# CH32H417 register map
Vendor: WCH Ltd.; File version: 1.2
Registers are 32-bit, read-write, reset 0x0 unless marked. A register's access mark holds for its fields unless they carry their own. Offsets are from the block's base; [hi:lo] are bit positions.

## ECDC
Base 0x40016C00
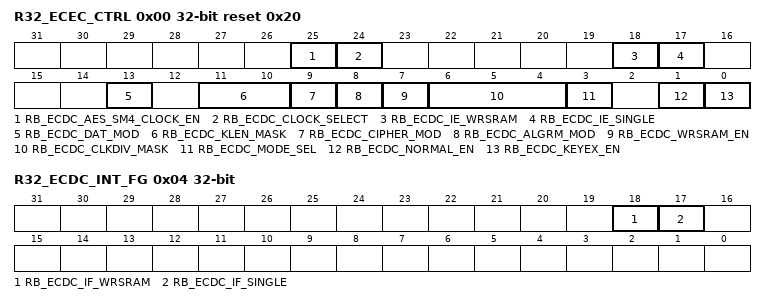
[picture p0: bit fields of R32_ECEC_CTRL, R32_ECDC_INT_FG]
0x00 R32_ECEC_CTRL access per field reset 0x20 — ECED AES/SM4 register
  [25] RB_ECDC_AES_SM4_CLOCK_EN rw — ECED AES/SM4 clock enabled
  [24] RB_ECDC_CLOCK_SELECT rw — ECED AES/SM4 clock selection
  [18] RB_ECDC_IE_WRSRAM wo — Memory to memory encryption and decryption completion interrupt enable
  [17] RB_ECDC_IE_SINGLE rw — Single encryption and decryption completion interrupt enable
  [13] RB_ECDC_DAT_MOD wo — source data and result data is bit endian
  [11:10] RB_ECDC_KLEN_MASK rw — Key length setting
  [9] RB_ECDC_CIPHER_MOD rw — Block cipher mode selection
  [8] RB_ECDC_ALGRM_MOD rw — Encryption and decryption algorithm mode selection
  [7] RB_ECDC_WRSRAM_EN rw — module dma enable
  [6:4] RB_ECDC_CLKDIV_MASK rw — Clock divide factor
  [3] RB_ECDC_MODE_SEL rw — ECDC mode select
  [1] RB_ECDC_NORMAL_EN rw — Enable the encryption and decryption to work in the normal encryption and decryption mode
  [0] RB_ECDC_KEYEX_EN rw — enable key expansion
0x04 R32_ECDC_INT_FG — Interupt flag register
  [18] RB_ECDC_IF_WRSRAM — Memory to memory encryption and decryption completion interrupt flag
  [17] RB_ECDC_IF_SINGLE — Single encryption and decryption completion interrupt flag
0x08 R32_ECDC_KEY_255T224 — User key 224-255 register
  [31:0] RB_ECDC_KEY_255T224
0x0C R32_ECDC_KEY_223T192 — User key 192-223 register
  [31:0] RB_ECDC_KEY_223T192
0x10 R32_ECDC_KEY_191T160 — User key 160-191 register
  [31:0] RB_ECDC_KEY_191T160
0x14 R32_ECDC_KEY_159T128 — User key 128-159 register
  [31:0] RB_ECDC_KEY_159T128
0x18 R32_ECDC_KEY_127T96 — User key 96-127 register
  [31:0] RB_ECDC_KEY_127T96
0x1C R32_ECDC_KEY_95T64 — User key 64-95 register
  [31:0] RB_ECDC_KEY_95T64
0x20 R32_ECDC_KEY_63T32 — User key 32-63 register
  [31:0] RB_ECDC_KEY_63T32
0x24 R32_ECDC_KEY_31T0 — User key 0-31 register
  [31:0] RB_ECDC_KEY_31T0
0x28 R32_ECDC_IV_127T96 — CTR mode count 96-127 register
  [31:0] RB_ECDC_IV_127T96
0x2C R32_ECDC_IV_95T64 — CTR mode count 64-95 register
  [31:0] RB_ECDC_IV_95T64
0x30 R32_ECDC_IV_63T32 — CTR mode count 32-63 register
  [31:0] RB_ECDC_IV_63T32
0x34 R32_ECDC_IV_31T0 — CTR mode count 0-31 register
  [31:0] RB_ECDC_IV_31T0
0x40 R32_ECDC_SGSD_127T96 — Single encryption and decryption of original data 96-127 register
  [31:0] RB_ECDC_SGSD_127T96
0x44 R32_ECDC_SGSD_95T64 — Single encryption and decryption of original data 64-95 register
  [31:0] RB_ECDC_SGSD_95T64
0x48 R32_ECDC_SGSD_63T32 — Single encryption and decryption of original data 32-63 register
  [31:0] RB_ECDC_SGSD_63T32
0x4C R32_ECDC_SGSD_31T0 — Single encryption and decryption of original data 0-31 register
  [31:0] RB_ECDC_SGSD_31T0
0x50 R32_ECDC_SGRT_127T96 — Single encryption and decryption result 96-127 register
  [31:0] RB_ECDC_SGRT_127T96
0x54 R32_ECDC_SGRT_95T64 — Single encryption and decryption result 64-95 register
  [31:0] RB_ECDC_SGRT_95T64
0x58 R32_ECDC_SGRT_63T32 — Single encryption and decryption result 0-31 register
  [31:0] RB_ECDC_SGRT_63T32
0x5C RB_ECDC_SGRT_31T0 — Single encryption and decryption result 0-31 register
0x60 R32_ECDC_SRC_ADDR — encryption and decryption sram start address register
  [31:0] RB_ECDC_SRC_ADDR
0x64 R32_ECDC_DST_ADDR — encryption and decryption sram destination address register
  [31:0] RB_ECDC_DST_ADDR
0x68 R32_ECDC_SRAM_LEN — encryption and decryption sram size register
  [12:0] RB_ECDC_SRAM_LEN

## HSADC — High speed ADC
Base 0x40017400
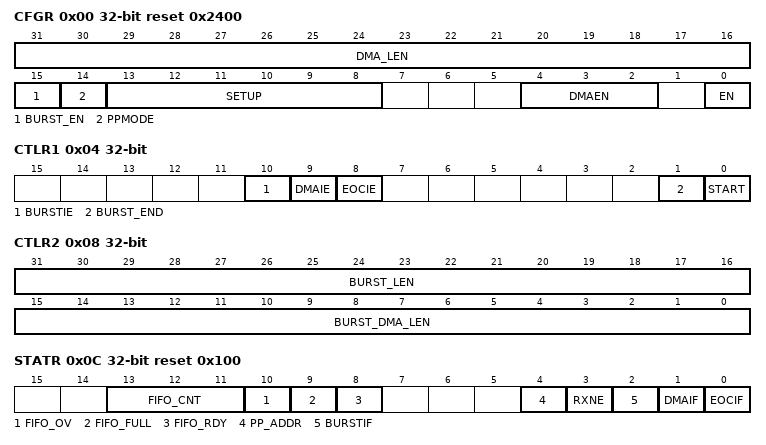
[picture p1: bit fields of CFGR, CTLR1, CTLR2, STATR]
0x00 CFGR reset 0x2400 — High-speed ADC configuration register
  [31:16] DMA_LEN — DMA transmission length configuration bit
  [15] BURST_EN — DMA transmission length configuration bit
  [14] PPMODE — Ping Pong storage mode enable
  [13:8] SETUP — First Transition Establishment Time Configuration Bit
  [4:2] DMAEN — Direct Storage Access (DMA) mode enable
  [0] EN — High-speed ADC enable
0x04 CTLR1 access per field — HSADC Control Register 1
  [10] BURSTIE rw — Interrupt enables when the burst transmission is complete
  [9] DMAIE rw — Transition Completion Interrupt Enables
  [8] EOCIE rw — Transition Completion Interrupt Enables
  [1] BURST_END rw — Abort a burst transmission
  [0] START wo — Initiating High-Speed ADC Conversion
0x08 CTLR2 — HSADC Control Register 2
  [31:16] BURST_LEN — Burst transmission length configuration
  [15:0] BURST_DMA_LEN — The final DMA transmission length configuration bit for burst transmission. If the number of data transmitted in the final burst is not aligned with the DMA transmission length, the DMA transmission length is configured
0x0C STATR access per field reset 0x100 — HSADC Status Register
  [13:11] FIFO_CNT ro — Receives the FIFO current count value
  [10] FIFO_OV ro — Receives the FIFO overflow status flag
  [9] FIFO_FULL ro — Receive FIFO full status flags
  [8] FIFO_RDY ro — Receives a FIFO non-null status flag
  [4] PP_ADDR ro — Ping-pong storage mode cache address indicator bit
  [3] RXNE ro — The data register is not empty flag, that is, the conversion is completed and the data is stored in the data register, which is the position bit; A read operation on the data register clears the bit
  [2] BURSTIF rw — Burst transfer completed interrupt flag
  [1] DMAIF rw — DMA Transmission Complete Interrupt flag
  [0] EOCIF rw — Transition Complete Interrupt flag
0x10 DATAR — HSADC Data Register
  [9:0] DR — Convert data register
0x14 ADDR0 — HSADC DMA Receive Address Register 0
  [31:0] DMA_ADDR0 — The DMA transmission address is configured with the 0 configuration bit
0x18 ADDR1 — HSADC DMA Receive Address Register 1
  [31:0] DMA_ADDR1 — DMA transport address 1 configuration bit
